# I94100_v1_3 register map
File version: 1.0
Registers are 32-bit, read-write, reset 0x0 unless marked. A register's access mark holds for its fields unless they carry their own. Offsets are from the block's base; [hi:lo] are bit positions.

## WDT — WDT Register Map
Base 0x40040000
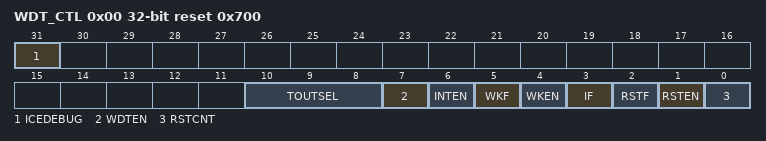
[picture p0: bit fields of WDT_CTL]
0x00 WDT_CTL reset 0x700 (reset mask 0xFFFFFF0F) — WDT Control Register
  [31] ICEDEBUG — ICE Debug Mode Acknowledge Disable Control (Write Protected). WDT up counter will keep going no matter CPU is held by ICE or not. Note: This bit is write protected. Refer to the SYS_REGLCTL register.
    0=ICE debug mode acknowledgement affects WDT counting; 1=ICE debug mode acknowledgement Disabled
  [10:8] TOUTSEL — WDT Time-out Interval Selection (Write Protected). These three bits select the time-out interval period for the WDT. Note: This bit is write protected. Refer to the SYS_REGLCTL register.
    0=24 * WDT_CLK; 1=26 * WDT_CLK; 2=28 * WDT_CLK; 3=210 * WDT_CLK; 4=212 * WDT_CLK; 5=214 * WDT_CLK; 6=216 * WDT_CLK; 7=218 * WDT_CLK
  [7] WDTEN — WDT Enable Control (Write Protected). Note1: This bit is write protected. Refer to the SYS_REGLCTL register. Note2: If CWDTEN[2:0] (combined by Config0[31] and Config0[4:3]) bits is not configure to 111, this bit is forced as 1 and user cannot change this bit to 0.
    0=WDT Disabled (This action will reset the internal up counter value); 1=WDT Enabled
  [6] INTEN — WDT Time-out Interrupt Enable Control (Write Protected). If this bit is enabled, the WDT time-out interrupt signal is generated and inform to CPU. Note1: This bit is write protected. Refer to the SYS_REGLCTL register. Note2: The reset value of this bit is 0.
    0=WDT time-out interrupt Disabled; 1=WDT time-out interrupt Enabled
  [5] WKF — WDT Time-out Wake-up Flag (Write Protected). This bit indicates the interrupt wake-up flag status of WDT. Note1: This bit is write protected. Refer to the SYS_REGLCTL register. Note2: This bit is cleared by writing 1 to it. Note3: The reset value of this bit is 0.
    0=WDT does not cause chip wake-up; 1=Chip wake-up from Idle or Power-down mode if WDT time-out interrupt signal generated
  [4] WKEN — WDT Time-out Wake-up Function Control (Write Protected). If this bit is set to 1, while WDT time-out interrupt flag IF (WDT_CTL[3]) is generated to 1 and interrupt enable bit INTEN (WDT_CTL[6]) is enabled, the WDT time-out interrupt signal will generate a wake-up trigger event to chip. Note1: This bit is write protected. Refer to the SYS_REGLCTL register. Note2: Chip can be woken-up by WDT time-out interrupt signal generated only if WDT clock source is selected to 10 kHz internal low speed RC oscillator (LIRC) or LXT. Note3: The reset value of this bit is 0.
    0=Wake-up trigger event Disabled if WDT time-out interrupt signal generated; 1=Wake-up trigger event Enabled if WDT time-out interrupt signal generated
  [3] IF — WDT Time-out Interrupt Flag. This bit will set to 1 while WDT up counter value reaches the selected WDT time-out interval. Note: This bit is cleared by writing 1 to it.
    0=WDT time-out interrupt did not occur; 1=WDT time-out interrupt occurred
  [2] RSTF — WDT Time-out Reset Flag. This bit indicates the system has been reset by WDT time-out reset or not. Note: This bit is cleared by writing 1 to it.
    0=WDT time-out reset did not occur; 1=WDT time-out reset occurred
  [1] RSTEN — WDT Time-out Reset Enable Control (Write Protected). Setting this bit will enable the WDT time-out reset function If the WDT up counter value has not been cleared after the specific WDT reset delay period expires. Note: This bit is write protected. Refer to the SYS_REGLCTL register.
    0=WDT time-out reset function Disabled; 1=WDT time-out reset function Enabled
  [0] RSTCNT — Reset WDT Up Counter (Write Protected). Note1: This bit is write protected. Refer to the SYS_REGLCTL register. Note2: This bit will be automatically cleared by hardware.
    0=No effect; 1=Reset the internal 18-bit WDT up counter value
0x04 WDT_ALTCTL — WDT Alternative Control Register
  [1:0] RSTDSEL — WDT Reset Delay Selection (Write Protected). When WDT time-out happened, user has a time named WDT Reset Delay Period to clear WDT counter by setting RSTCNT (WDT_CTL[0]) to prevent WDT time-out reset happened. User can select a suitable setting of RSTDSEL for different WDT Reset Delay Period. Note1: This bit is write protected. Refer to the SYS_REGLCTL register. Note2: This register will be reset to 0 if WDT time-out reset happened.
    0=WDT Reset Delay Period is 1026 * WDT_CLK; 1=WDT Reset Delay Period is 130 * WDT_CLK; 2=WDT Reset Delay Period is 18 * WDT_CLK; 3=WDT Reset Delay Period is 3 * WDT_CLK
